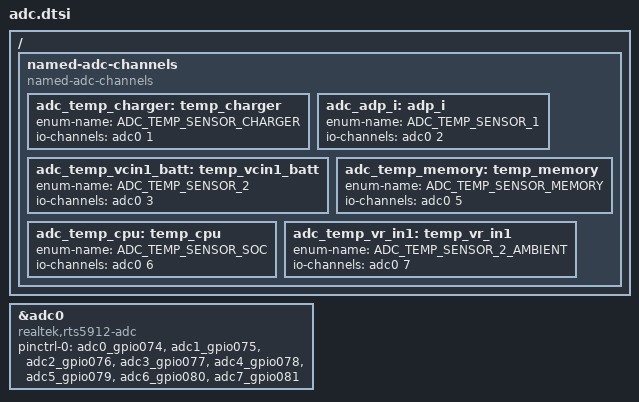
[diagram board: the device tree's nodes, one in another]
/* Copyright 2025 The ChromiumOS Authors
 * Use of this source code is governed by a BSD-style license that can be
 * found in the LICENSE file.
 */

 / {
	named-adc-channels {
		compatible = "named-adc-channels";

		adc_temp_charger: temp_charger {
			enum-name = "ADC_TEMP_SENSOR_CHARGER";
			io-channels = <&adc0 1>;
		};
		adc_adp_i: adp_i {
			enum-name = "ADC_TEMP_SENSOR_1";
			io-channels = <&adc0 2>;
		};
		adc_temp_vcin1_batt: temp_vcin1_batt {
			enum-name = "ADC_TEMP_SENSOR_2";
			io-channels = <&adc0 3>;
		};
		adc_temp_memory: temp_memory {
			enum-name = "ADC_TEMP_SENSOR_MEMORY";
			io-channels = <&adc0 5>;
		};
		adc_temp_cpu: temp_cpu {
			enum-name = "ADC_TEMP_SENSOR_SOC";
			io-channels = <&adc0 6>;
		};
		adc_temp_vr_in1: temp_vr_in1 {
			enum-name = "ADC_TEMP_SENSOR_2_AMBIENT";
			io-channels = <&adc0 7>;
		};
	};
};

&adc0 {
	compatible = "realtek,rts5912-adc";
	pinctrl-0 = <&adc0_gpio074
		&adc1_gpio075
		&adc2_gpio076
		&adc3_gpio077
		&adc4_gpio078
		&adc5_gpio079
		&adc6_gpio080
		&adc7_gpio081
	>;
	pinctrl-names = "default";
	status = "okay";
};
